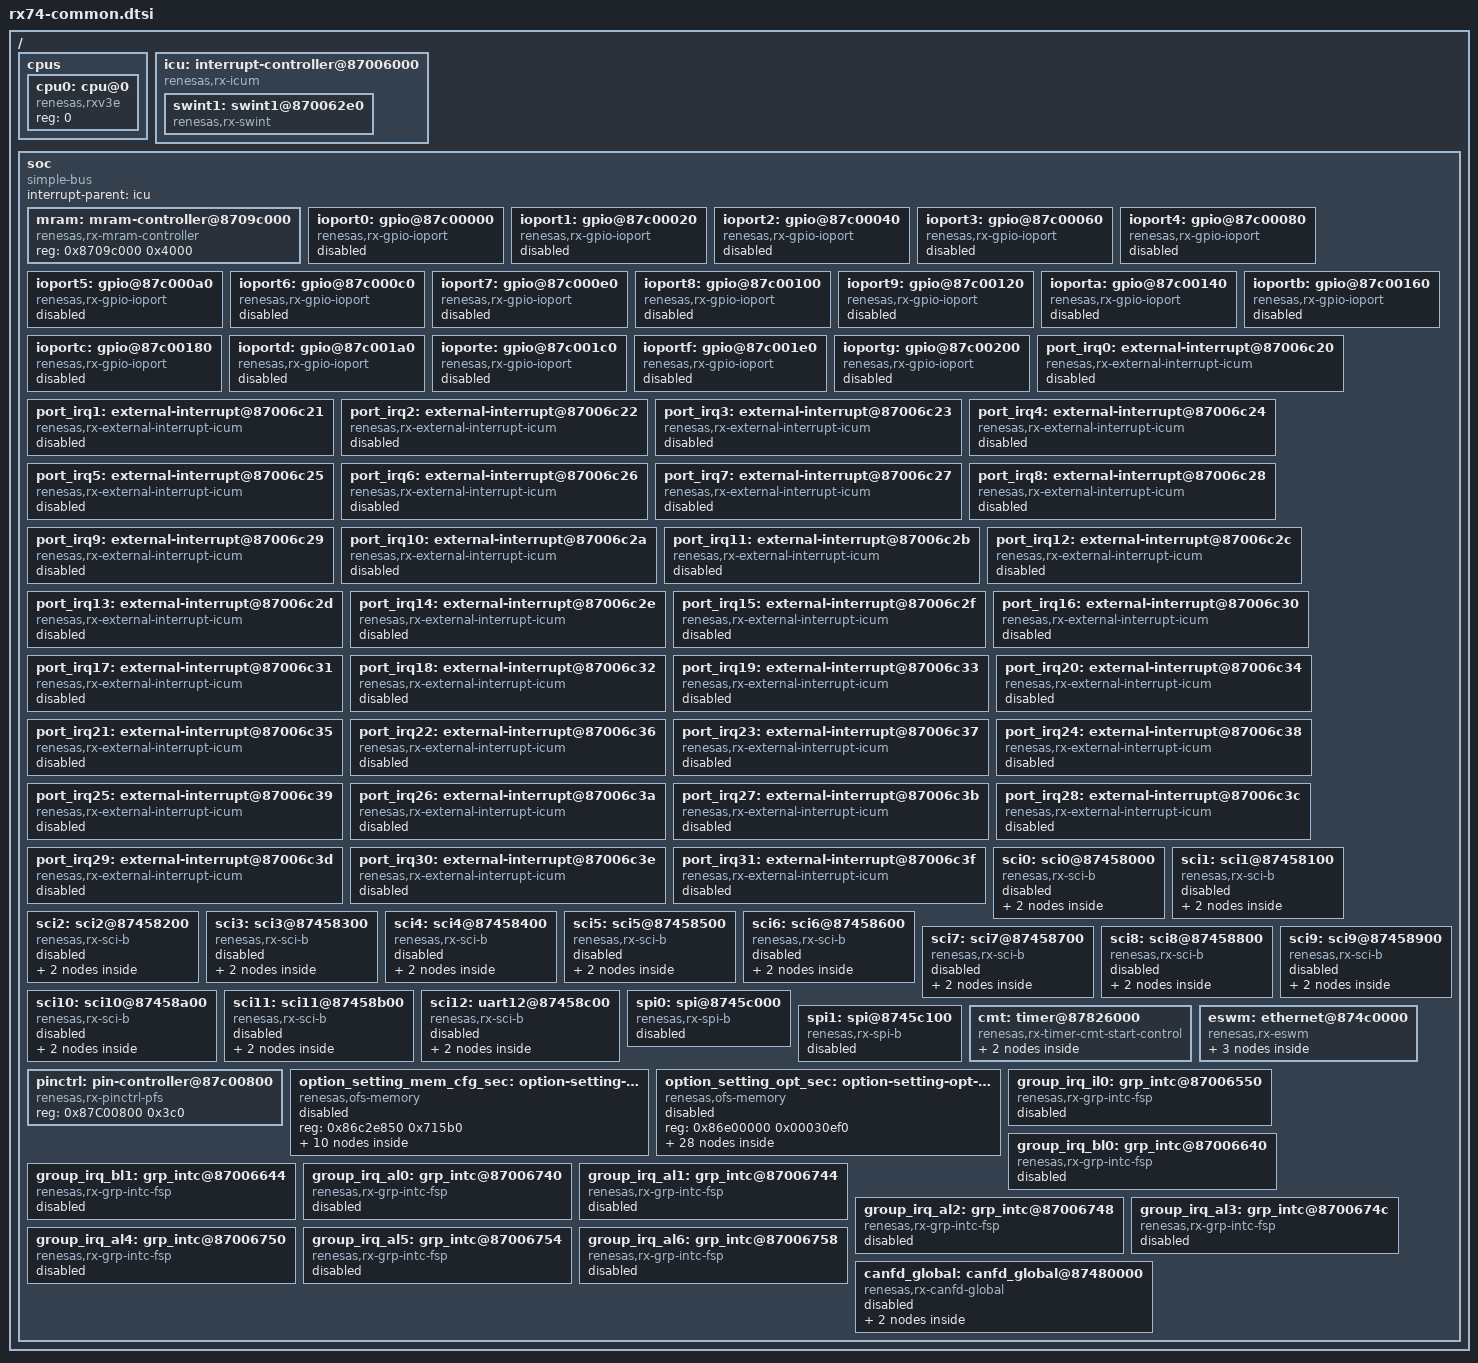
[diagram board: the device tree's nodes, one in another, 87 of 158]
/*
* Copyright (c) 2025 Renesas Electronics Corporation
*
* SPDX-License-Identifier: Apache-2.0
*/

#include <mem.h>
#include <zephyr/dt-bindings/clock/rx_clock.h>
#include <zephyr/dt-bindings/pinctrl/renesas/pinctrl-rx-pfs.h>

/ {
	#address-cells = <1>;
	#size-cells = <1>;

	cpus {
		#address-cells = <1>;
		#size-cells = <0>;

		cpu0: cpu@0 {
			compatible = "renesas,rxv3e";
			device_type = "cpu";
			reg = <0>;
			status = "okay";
		};
	};

	icu: interrupt-controller@87006000 {
		#interrupt-cells = <2>;
		#address-cells = <1>;
		#size-cells = <1>;
		compatible = "renesas,rx-icum";
		interrupt-controller;
		reg = <0x87006000 0x100>,
		<0x87006200 0x20>,
		<0x87006300 0x100>,
		<0x870062f0 0x02>,
		<0x87006c20 0x20>,
		<0x87006900 0x20>;
		reg-names = "IR", "IER", "IPR", "FIR", "IRQCR", "SLIXR";

		swint1: swint1@870062e0 {
			compatible = "renesas,rx-swint";
			reg = <0x870062e0 0x01>;
			interrupts = <27 14>;
			interrupt-parent = <&icu>;
			status = "okay";
		};
	};

	soc {
		#address-cells = <1>;
		#size-cells = <1>;
		device_type = "soc";
		compatible = "simple-bus";
		interrupt-parent = <&icu>;

		mram: mram-controller@8709c000 {
			compatible = "renesas,rx-mram-controller";
			reg = <0x8709c000 0x4000>;
			#address-cells = <1>;
			#size-cells = <1>;
			status = "okay";
		};

		ioport0: gpio@87c00000 {
			compatible = "renesas,rx-gpio-ioport";
			reg = <0x87C00000 0x20>;
			port = <0>;
			gpio-controller;
			#gpio-cells = <2>;
			ngpios = <16>;
			port-irqs = <&port_irq16 &port_irq17 &port_irq18 &port_irq19
			&port_irq20 &port_irq21 &port_irq22 &port_irq23
			&port_irq24 &port_irq25 &port_irq26 &port_irq27
			&port_irq28 &port_irq29 &port_irq30 &port_irq31>;
			port-irq-names = "port-irq16",
							 "port-irq17",
			                 "port-irq18",
			                 "port-irq19",
			                 "port-irq20",
			                 "port-irq21",
			                 "port-irq22",
			                 "port-irq23",
							 "port-irq24",
							 "port-irq25",
			                 "port-irq26",
			                 "port-irq27",
			                 "port-irq28",
			                 "port-irq29",
			                 "port-irq30",
			                 "port-irq31";
			port-irq16-pins = <0>;
			port-irq17-pins = <1>;
			port-irq18-pins = <2>;
			port-irq19-pins = <3>;
			port-irq20-pins = <4>;
			port-irq21-pins = <5>;
			port-irq22-pins = <6>;
			port-irq23-pins = <7>;
			port-irq24-pins = <8>;
			port-irq25-pins = <9>;
			port-irq26-pins = <10>;
			port-irq27-pins = <11>;
			port-irq28-pins = <12>;
			port-irq29-pins = <13>;
			port-irq30-pins = <14>;
			port-irq31-pins = <15>;
			status = "disabled";
		};

		ioport1: gpio@87c00020 {
			compatible = "renesas,rx-gpio-ioport";
			reg = <0x87C00020 0x20>;
			port = <1>;
			gpio-controller;
			#gpio-cells = <2>;
			ngpios = <16>;
			port-irqs = <&port_irq0 &port_irq1 &port_irq2 &port_irq3
			&port_irq4 &port_irq29 &port_irq30 &port_irq31
			&port_irq16 &port_irq17 &port_irq18 &port_irq19
			&port_irq20 &port_irq21 &port_irq22 &port_irq23>;
			port-irq-names = "port-irq0",
							 "port-irq1",
			                 "port-irq2",
			                 "port-irq3",
			                 "port-irq4",
			                 "port-irq29",
			                 "port-irq30",
			                 "port-irq31",
							 "port-irq16",
							 "port-irq17",
			                 "port-irq18",
			                 "port-irq19",
			                 "port-irq20",
			                 "port-irq21",
			                 "port-irq22",
			                 "port-irq23";
			port-irq0-pins = <0>;
			port-irq1-pins = <1>;
			port-irq2-pins = <2>;
			port-irq3-pins = <3>;
			port-irq4-pins = <4>;
			port-irq29-pins = <5>;
			port-irq30-pins = <6>;
			port-irq31-pins = <7>;
			port-irq16-pins = <8>;
			port-irq17-pins = <9>;
			port-irq18-pins = <10>;
			port-irq19-pins = <11>;
			port-irq20-pins = <12>;
			port-irq21-pins = <13>;
			port-irq22-pins = <14>;
			port-irq23-pins = <15>;
			status = "disabled";
		};

		ioport2: gpio@87c00040 {
			compatible = "renesas,rx-gpio-ioport";
			reg = <0x87C00040 0x20>;
			port = <2>;
			gpio-controller;
			#gpio-cells = <2>;
			ngpios = <16>;
			port-irqs = <&port_irq8 &port_irq9 &port_irq15 &port_irq3
			&port_irq12 &port_irq5 &port_irq2 &port_irq24
			&port_irq25 &port_irq26 &port_irq27 &port_irq28
			&port_irq29 &port_irq30 &port_irq31>;
			port-irq-names = "port-irq8",
					 		 "port-irq9",
							 "port-irq15",
					 		 "port-irq3",
							 "port-irq12",
					 		 "port-irq5",
							 "port-irq2",
							 "port-irq24",
							 "port-irq25",
			                 "port-irq26",
			                 "port-irq27",
			                 "port-irq28",
			                 "port-irq29",
			                 "port-irq30",
			                 "port-irq31";
			port-irq8-pins = <0>;
			port-irq9-pins = <1>;
			port-irq15-pins = <2>;
			port-irq3-pins = <3 7>;
			port-irq12-pins = <4>;
			port-irq5-pins = <5>;
			port-irq2-pins = <6>;
			port-irq24-pins = <8>;
			port-irq25-pins = <9>;
			port-irq26-pins = <10>;
			port-irq27-pins = <11>;
			port-irq28-pins = <12>;
			port-irq29-pins = <13>;
			port-irq30-pins = <14>;
			port-irq31-pins = <15>;
			status = "disabled";
		};

		ioport3: gpio@87c00060 {
			compatible = "renesas,rx-gpio-ioport";
			reg = <0x87C00060 0x20>;
			port = <3>;
			gpio-controller;
			#gpio-cells = <2>;
			ngpios = <16>;
			port-irqs = <&port_irq6 &port_irq7 &port_irq4 &port_irq1
			&port_irq0 &port_irq18 &port_irq19 &port_irq20>;
			port-irq-names = "port-irq6",
			                 "port-irq7",
			                 "port-irq4",
			                 "port-irq1",
			                 "port-irq0",
			                 "port-irq18",
			                 "port-irq19",
			                 "port-irq20";
			port-irq6-pins = <0>;
			port-irq7-pins = <1>;
			port-irq4-pins = <2>;
			port-irq1-pins = <3>;
			port-irq0-pins = <4 5>;
			port-irq18-pins = <10>;
			port-irq19-pins = <11>;
			port-irq20-pins = <12>;
			status = "disabled";
		};

		ioport4: gpio@87c00080 {
			compatible = "renesas,rx-gpio-ioport";
			reg = <0x87C00080 0x20>;
			port = <4>;
			gpio-controller;
			#gpio-cells = <2>;
			ngpios = <16>;
			port-irqs = <&port_irq8 &port_irq9 &port_irq10 &port_irq11
			&port_irq12 &port_irq13 &port_irq14 &port_irq15
			&port_irq24 &port_irq25 &port_irq26 &port_irq27
			&port_irq28 &port_irq29 &port_irq30 &port_irq31>;
			port-irq-names = "port-irq8",
							 "port-irq9",
			                 "port-irq10",
			                 "port-irq11",
			                 "port-irq12",
			                 "port-irq13",
			                 "port-irq14",
			                 "port-irq15",
							 "port-irq24",
							 "port-irq25",
			                 "port-irq26",
			                 "port-irq27",
			                 "port-irq28",
			                 "port-irq29",
			                 "port-irq30",
			                 "port-irq31";
			port-irq8-pins = <0>;
			port-irq9-pins = <1>;
			port-irq10-pins = <2>;
			port-irq11-pins = <3>;
			port-irq12-pins = <4>;
			port-irq13-pins = <5>;
			port-irq14-pins = <6>;
			port-irq15-pins = <7>;
			port-irq24-pins = <8>;
			port-irq25-pins = <9>;
			port-irq26-pins = <10>;
			port-irq27-pins = <11>;
			port-irq28-pins = <12>;
			port-irq29-pins = <13>;
			port-irq30-pins = <14>;
			port-irq31-pins = <15>;
			status = "disabled";
		};

		ioport5: gpio@87c000a0 {
			compatible = "renesas,rx-gpio-ioport";
			reg = <0x87C000A0 0x20>;
			port = <5>;
			gpio-controller;
			#gpio-cells = <2>;
			ngpios = <16>;
			port-irqs = <&port_irq0 &port_irq1 &port_irq2 &port_irq3
			&port_irq4 &port_irq10 &port_irq6 &port_irq7
			&port_irq16 &port_irq17 &port_irq18 &port_irq19
			&port_irq20 &port_irq21 &port_irq22 &port_irq23>;
			port-irq-names = "port-irq0",
							 "port-irq1",
			                 "port-irq2",
			                 "port-irq3",
			                 "port-irq4",
			                 "port-irq10",
			                 "port-irq6",
			                 "port-irq7",
							 "port-irq16",
							 "port-irq17",
			                 "port-irq18",
			                 "port-irq19",
			                 "port-irq20",
			                 "port-irq21",
			                 "port-irq22",
			                 "port-irq23";
			port-irq0-pins = <0>;
			port-irq1-pins = <1>;
			port-irq2-pins = <2>;
			port-irq3-pins = <3>;
			port-irq4-pins = <4>;
			port-irq10-pins = <5>;
			port-irq6-pins = <6>;
			port-irq7-pins = <7>;
			port-irq16-pins = <8>;
			port-irq17-pins = <9>;
			port-irq18-pins = <10>;
			port-irq19-pins = <11>;
			port-irq20-pins = <12>;
			port-irq21-pins = <13>;
			port-irq22-pins = <14>;
			port-irq23-pins = <15>;
			status = "disabled";
		};

		ioport6: gpio@87c000c0 {
			compatible = "renesas,rx-gpio-ioport";
			reg = <0x87C000C0 0x20>;
			port = <6>;
			gpio-controller;
			#gpio-cells = <2>;
			ngpios = <8>;
			port-irqs = <&port_irq0 &port_irq1 &port_irq2 &port_irq3
			&port_irq4 &port_irq13 &port_irq14 &port_irq15>;
			port-irq-names = "port-irq0",
							 "port-irq1",
			                 "port-irq2",
			                 "port-irq3",
			                 "port-irq4",
			                 "port-irq13",
			                 "port-irq14",
			                 "port-irq15";
			port-irq0-pins = <0>;
			port-irq1-pins = <1>;
			port-irq2-pins = <2>;
			port-irq3-pins = <3>;
			port-irq4-pins = <4>;
			port-irq13-pins = <5>;
			port-irq14-pins = <6>;
			port-irq15-pins = <7>;
			status = "disabled";
		};

		ioport7: gpio@87c000e0 {
			compatible = "renesas,rx-gpio-ioport";
			reg = <0x87C000E0 0x20>;
			port = <7>;
			gpio-controller;
			#gpio-cells = <2>;
			ngpios = <16>;
			port-irqs = <&port_irq0 &port_irq1 &port_irq10 &port_irq8
			&port_irq12 &port_irq13 &port_irq14 &port_irq7
			&port_irq16 &port_irq17 &port_irq18 &port_irq19
			&port_irq20 &port_irq21 &port_irq22 &port_irq23>;
			port-irq-names = "port-irq0",
							 "port-irq1",
			                 "port-irq10",
			                 "port-irq8",
			                 "port-irq12",
			                 "port-irq13",
			                 "port-irq14",
			                 "port-irq7",
							 "port-irq16",
							 "port-irq17",
			                 "port-irq18",
			                 "port-irq19",
			                 "port-irq20",
			                 "port-irq21",
			                 "port-irq22",
			                 "port-irq23";
			port-irq0-pins = <0>;
			port-irq1-pins = <1>;
			port-irq10-pins = <2>;
			port-irq8-pins = <3>;
			port-irq12-pins = <4>;
			port-irq13-pins = <5>;
			port-irq14-pins = <6>;
			port-irq7-pins = <7>;
			port-irq16-pins = <8>;
			port-irq17-pins = <9>;
			port-irq18-pins = <10>;
			port-irq19-pins = <11>;
			port-irq20-pins = <12>;
			port-irq21-pins = <13>;
			port-irq22-pins = <14>;
			port-irq23-pins = <15>;
			status = "disabled";
		};

		ioport8: gpio@87c00100 {
			compatible = "renesas,rx-gpio-ioport";
			reg = <0x87C00100 0x20>;
			port = <8>;
			gpio-controller;
			#gpio-cells = <2>;
			ngpios = <16>;
			port-irqs = <&port_irq8 &port_irq9 &port_irq2 &port_irq3
			&port_irq4 &port_irq5 &port_irq14 &port_irq15>;
			port-irq-names = "port-irq8",
							 "port-irq9",
			                 "port-irq2",
			                 "port-irq3",
			                 "port-irq4",
			                 "port-irq5",
			                 "port-irq14",
			                 "port-irq15";
			port-irq8-pins = <0>;
			port-irq9-pins = <1>;
			port-irq2-pins = <2>;
			port-irq3-pins = <3>;
			port-irq4-pins = <4>;
			port-irq5-pins = <5>;
			port-irq14-pins = <6>;
			port-irq15-pins = <7>;
			status = "disabled";
		};

		ioport9: gpio@87c00120 {
			compatible = "renesas,rx-gpio-ioport";
			reg = <0x87C00120 0x20>;
			port = <9>;
			gpio-controller;
			#gpio-cells = <2>;
			ngpios = <16>;
			port-irqs = <&port_irq0 &port_irq9 &port_irq10 &port_irq11
			&port_irq12 &port_irq13 &port_irq14 &port_irq15>;
			port-irq-names = "port-irq0",
							 "port-irq9",
			                 "port-irq10",
			                 "port-irq11",
			                 "port-irq12",
			                 "port-irq13",
			                 "port-irq14",
			                 "port-irq15";
			port-irq0-pins = <0>;
			port-irq9-pins = <1>;
			port-irq10-pins = <2>;
			port-irq11-pins = <3>;
			port-irq12-pins = <4>;
			port-irq13-pins = <5>;
			port-irq14-pins = <6>;
			port-irq15-pins = <7>;
			status = "disabled";
		};

		ioporta: gpio@87c00140 {
			compatible = "renesas,rx-gpio-ioport";
			reg = <0x87C00140 0x20>;
			port = <10>;
			gpio-controller;
			#gpio-cells = <2>;
			ngpios = <8>;
			port-irqs = <&port_irq1 &port_irq5 &port_irq6 &port_irq7
			&port_irq10 &port_irq11 &port_irq14>;
			port-irq-names = "port-irq1",
			                 "port-irq5",
			                 "port-irq6",
			                 "port-irq7",
			                 "port-irq10",
			                 "port-irq11",
			                 "port-irq14";
			port-irq1-pins = <0>;
			port-irq5-pins = <4 5>;
			port-irq6-pins = <3>;
			port-irq7-pins = <7>;
			port-irq10-pins = <2>;
			port-irq11-pins = <1>;
			port-irq14-pins = <6>;
			status = "disabled";
		};

		ioportb: gpio@87c00160 {
			compatible = "renesas,rx-gpio-ioport";
			reg = <0x87C00160 0x20>;
			port = <11>;
			gpio-controller;
			#gpio-cells = <2>;
			ngpios = <8>;
			port-irqs = <&port_irq12 &port_irq4 &port_irq2 &port_irq3
			&port_irq13 &port_irq6 &port_irq15>;
			port-irq-names = "port-irq12",
			                 "port-irq4",
			                 "port-irq2",
			                 "port-irq3",
			                 "port-irq13",
			                 "port-irq6",
							 "port-irq15";
			port-irq12-pins = <0>;
			port-irq4-pins = <1 4>;
			port-irq2-pins = <2>;
			port-irq3-pins = <3>;
			port-irq13-pins = <5>;
			port-irq6-pins = <6>;
			port-irq15-pins = <15>;
			status = "disabled";
		};

		ioportc: gpio@87c00180 {
			compatible = "renesas,rx-gpio-ioport";
			reg = <0x87C00180 0x20>;
			port = <12>;
			gpio-controller;
			#gpio-cells = <2>;
			ngpios = <8>;
			port-irqs = <&port_irq14 &port_irq10 &port_irq11 &port_irq12
			&port_irq5 &port_irq13 &port_irq14>;
			port-irq-names = "port-irq14",
			                 "port-irq10",
			                 "port-irq11",
			                 "port-irq12",
			                 "port-irq5",
			                 "port-irq13",
			                 "port-irq14";
			port-irq14-pins = <0>;
			port-irq10-pins = <2>;
			port-irq12-pins = <1 4>;
			port-irq11-pins = <3>;
			port-irq5-pins = <5>;
			port-irq13-pins = <6>;
			port-irq14-pins = <7>;
			status = "disabled";
		};

		ioportd: gpio@87c001a0 {
			compatible = "renesas,rx-gpio-ioport";
			reg = <0x87C001A0 0x20>;
			port = <13>;
			gpio-controller;
			#gpio-cells = <2>;
			ngpios = <8>;
			port-irqs = <&port_irq0 &port_irq1 &port_irq2 &port_irq3
			&port_irq4 &port_irq5 &port_irq6 &port_irq7>;
			port-irq-names = "port-irq0",
			                 "port-irq1",
			                 "port-irq2",
			                 "port-irq3",
			                 "port-irq4",
			                 "port-irq5",
			                 "port-irq6",
			                 "port-irq7";
			port-irq0-pins = <0>;
			port-irq1-pins = <1>;
			port-irq2-pins = <2>;
			port-irq3-pins = <3>;
			port-irq4-pins = <4>;
			port-irq5-pins = <5>;
			port-irq6-pins = <6>;
			port-irq7-pins = <7>;
			status = "disabled";
		};

		ioporte: gpio@87c001c0 {
			compatible = "renesas,rx-gpio-ioport";
			reg = <0x87C001C0 0x20>;
			port = <14>;
			gpio-controller;
			#gpio-cells = <2>;
			ngpios = <8>;
			port-irqs = <&port_irq8 &port_irq9 &port_irq7 &port_irq11
			&port_irq12 &port_irq5 &port_irq6>;
			port-irq-names = "port-irq8",
			                 "port-irq9",
			                 "port-irq7",
			                 "port-irq11",
			                 "port-irq12",
			                 "port-irq5",
			                 "port-irq6";
			port-irq8-pins = <0>;
			port-irq9-pins = <1>;
			port-irq7-pins = <2 7>;
			port-irq11-pins = <3>;
			port-irq12-pins = <4>;
			port-irq5-pins = <5>;
			port-irq6-pins = <6>;
			status = "disabled";
		};

		ioportf: gpio@87c001e0 {
			compatible = "renesas,rx-gpio-ioport";
			reg = <0x87C001E0 0x20>;
			port = <15>;
			gpio-controller;
			#gpio-cells = <2>;
			ngpios = <10>;
			port-irqs = <&port_irq16 &port_irq17>;
			port-irq-names = "port-irq16", "port-irq17";
			port-irq16-pins = <8>;
			port-irq17-pins = <9>;
			status = "disabled";
		};

		ioportg: gpio@87c00200 {
			compatible = "renesas,rx-gpio-ioport";
			reg = <0x87C00200 0x20>;
			port = <16>;
			gpio-controller;
			#gpio-cells = <2>;
			ngpios = <16>;
			port-irqs = <&port_irq8 &port_irq9 &port_irq10 &port_irq11
			&port_irq12 &port_irq13 &port_irq14 &port_irq15>;
			port-irq-names = "port-irq8",
							 "port-irq9",
			                 "port-irq10",
			                 "port-irq11",
			                 "port-irq12",
			                 "port-irq13",
			                 "port-irq14",
			                 "port-irq15";
			port-irq8-pins = <0>;
			port-irq9-pins = <1>;
			port-irq10-pins = <2>;
			port-irq11-pins = <3>;
			port-irq12-pins = <4>;
			port-irq13-pins = <5>;
			port-irq14-pins = <6>;
			port-irq15-pins = <7>;
			status = "disabled";
		};

		port_irq0: external-interrupt@87006c20 {
			compatible = "renesas,rx-external-interrupt-icum";
			reg = <0x87006C20 0x1>;
			interrupts = <64 12>;
			channel = <0>;
			renesas,sample-clock-div = <64>;
			#port-irq-cells = <0>;
			status = "disabled";
		};

		port_irq1: external-interrupt@87006c21 {
			compatible = "renesas,rx-external-interrupt-icum";
			reg = <0x87006C21 0x1>;
			interrupts = <65 12>;
			channel = <1>;
			renesas,sample-clock-div = <64>;
			#port-irq-cells = <0>;
			status = "disabled";
		};

		port_irq2: external-interrupt@87006c22 {
			compatible = "renesas,rx-external-interrupt-icum";
			reg = <0x87006C22 0x1>;
			interrupts = <66 12>;
			channel = <2>;
			renesas,sample-clock-div = <64>;
			#port-irq-cells = <0>;
			status = "disabled";
		};

		port_irq3: external-interrupt@87006c23 {
			compatible = "renesas,rx-external-interrupt-icum";
			reg = <0x87006C23 0x1>;
			interrupts = <67 12>;
			channel = <3>;
			renesas,sample-clock-div = <64>;
			#port-irq-cells = <0>;
			status = "disabled";
		};

		port_irq4: external-interrupt@87006c24 {
			compatible = "renesas,rx-external-interrupt-icum";
			reg = <0x87006C24 0x1>;
			interrupts = <68 12>;
			channel = <4>;
			renesas,sample-clock-div = <64>;
			#port-irq-cells = <0>;
			status = "disabled";
		};

		port_irq5: external-interrupt@87006c25 {
			compatible = "renesas,rx-external-interrupt-icum";
			reg = <0x87006C25 0x1>;
			interrupts = <69 12>;
			channel = <5>;
			renesas,sample-clock-div = <64>;
			#port-irq-cells = <0>;
			status = "disabled";
		};

		port_irq6: external-interrupt@87006c26 {
			compatible = "renesas,rx-external-interrupt-icum";
			reg = <0x87006C26 0x1>;
			interrupts = <70 12>;
			channel = <6>;
			renesas,sample-clock-div = <64>;
			#port-irq-cells = <0>;
			status = "disabled";
		};

		port_irq7: external-interrupt@87006c27 {
			compatible = "renesas,rx-external-interrupt-icum";
			reg = <0x87006C27 0x1>;
			interrupts = <71 12>;
			channel = <7>;
			renesas,sample-clock-div = <64>;
			#port-irq-cells = <0>;
			status = "disabled";
		};

		port_irq8: external-interrupt@87006c28 {
			compatible = "renesas,rx-external-interrupt-icum";
			reg = <0x87006C28 0x1>;
			interrupts = <72 12>;
			channel = <8>;
			renesas,sample-clock-div = <64>;
			#port-irq-cells = <0>;
			status = "disabled";
		};

		port_irq9: external-interrupt@87006c29 {
			compatible = "renesas,rx-external-interrupt-icum";
			reg = <0x87006C29 0x1>;
			interrupts = <73 12>;
			channel = <9>;
			renesas,sample-clock-div = <64>;
			#port-irq-cells = <0>;
			status = "disabled";
		};

		port_irq10: external-interrupt@87006c2a {
			compatible = "renesas,rx-external-interrupt-icum";
			reg = <0x87006C2a 0x1>;
			interrupts = <74 12>;
			channel = <10>;
			renesas,sample-clock-div = <64>;
			#port-irq-cells = <0>;
			status = "disabled";
		};

		port_irq11: external-interrupt@87006c2b {
			compatible = "renesas,rx-external-interrupt-icum";
			reg = <0x87006C2B 0x1>;
			interrupts = <75 12>;
			channel = <11>;
			renesas,sample-clock-div = <64>;
			#port-irq-cells = <0>;
			status = "disabled";
		};

		port_irq12: external-interrupt@87006c2c {
			compatible = "renesas,rx-external-interrupt-icum";
			reg = <0x87006C2C 0x1>;
			interrupts = <76 12>;
			channel = <12>;
			renesas,sample-clock-div = <64>;
			#port-irq-cells = <0>;
			status = "disabled";
		};

		port_irq13: external-interrupt@87006c2d {
			compatible = "renesas,rx-external-interrupt-icum";
			reg = <0x87006C2D 0x1>;
			interrupts = <77 12>;
			channel = <13>;
			renesas,sample-clock-div = <64>;
			#port-irq-cells = <0>;
			status = "disabled";
		};

		port_irq14: external-interrupt@87006c2e {
			compatible = "renesas,rx-external-interrupt-icum";
			reg = <0x87006C2E 0x1>;
			interrupts = <78 12>;
			channel = <14>;
			renesas,sample-clock-div = <64>;
			#port-irq-cells = <0>;
			status = "disabled";
		};

		port_irq15: external-interrupt@87006c2f {
			compatible = "renesas,rx-external-interrupt-icum";
			reg = <0x87006C2F 0x1>;
			interrupts = <79 12>;
			channel = <15>;
			renesas,sample-clock-div = <64>;
			#port-irq-cells = <0>;
			status = "disabled";
		};

		port_irq16: external-interrupt@87006c30 {
			compatible = "renesas,rx-external-interrupt-icum";
			reg = <0x87006C30 0x1>;
			interrupts = <128 12>;
			channel = <16>;
			renesas,sample-clock-div = <64>;
			#port-irq-cells = <0>;
			status = "disabled";
		};

		port_irq17: external-interrupt@87006c31 {
			compatible = "renesas,rx-external-interrupt-icum";
			reg = <0x87006C31 0x1>;
			interrupts = <129 12>;
			channel = <17>;
			renesas,sample-clock-div = <64>;
			#port-irq-cells = <0>;
			status = "disabled";
		};

		port_irq18: external-interrupt@87006c32 {
			compatible = "renesas,rx-external-interrupt-icum";
			reg = <0x87006C32 0x1>;
			interrupts = <130 12>;
			channel = <18>;
			renesas,sample-clock-div = <64>;
			#port-irq-cells = <0>;
			status = "disabled";
		};

		port_irq19: external-interrupt@87006c33 {
			compatible = "renesas,rx-external-interrupt-icum";
			reg = <0x87006C33 0x1>;
			interrupts = <131 12>;
			channel = <19>;
			renesas,sample-clock-div = <64>;
			#port-irq-cells = <0>;
			status = "disabled";
		};

		port_irq20: external-interrupt@87006c34 {
			compatible = "renesas,rx-external-interrupt-icum";
			reg = <0x87006C34 0x1>;
			interrupts = <132 12>;
			channel = <20>;
			renesas,sample-clock-div = <64>;
			#port-irq-cells = <0>;
			status = "disabled";
		};

		port_irq21: external-interrupt@87006c35 {
			compatible = "renesas,rx-external-interrupt-icum";
			reg = <0x87006C35 0x1>;
			interrupts = <133 12>;
			channel = <21>;
			renesas,sample-clock-div = <64>;
			#port-irq-cells = <0>;
			status = "disabled";
		};

		port_irq22: external-interrupt@87006c36 {
			compatible = "renesas,rx-external-interrupt-icum";
			reg = <0x87006C36 0x1>;
			interrupts = <134 12>;
			channel = <22>;
			renesas,sample-clock-div = <64>;
			#port-irq-cells = <0>;
			status = "disabled";
		};

		port_irq23: external-interrupt@87006c37 {
			compatible = "renesas,rx-external-interrupt-icum";
			reg = <0x87006C37 0x1>;
			interrupts = <135 12>;
			channel = <23>;
			renesas,sample-clock-div = <64>;
			#port-irq-cells = <0>;
			status = "disabled";
		};

		port_irq24: external-interrupt@87006c38 {
			compatible = "renesas,rx-external-interrupt-icum";
			reg = <0x87006C38 0x1>;
			interrupts = <136 12>;
			channel = <24>;
			renesas,sample-clock-div = <64>;
			#port-irq-cells = <0>;
			status = "disabled";
		};

		port_irq25: external-interrupt@87006c39 {
			compatible = "renesas,rx-external-interrupt-icum";
			reg = <0x87006C39 0x1>;
			interrupts = <137 12>;
			channel = <25>;
			renesas,sample-clock-div = <64>;
			#port-irq-cells = <0>;
			status = "disabled";
		};

		port_irq26: external-interrupt@87006c3a {
			compatible = "renesas,rx-external-interrupt-icum";
			reg = <0x87006C3A 0x1>;
			interrupts = <138 12>;
			channel = <26>;
			renesas,sample-clock-div = <64>;
			#port-irq-cells = <0>;
			status = "disabled";
		};

		port_irq27: external-interrupt@87006c3b {
			compatible = "renesas,rx-external-interrupt-icum";
			reg = <0x87006C3B 0x1>;
			interrupts = <139 12>;
			channel = <27>;
			renesas,sample-clock-div = <64>;
			#port-irq-cells = <0>;
			status = "disabled";
		};

		port_irq28: external-interrupt@87006c3c {
			compatible = "renesas,rx-external-interrupt-icum";
			reg = <0x87006C3C 0x1>;
			interrupts = <140 12>;
			channel = <28>;
			renesas,sample-clock-div = <64>;
			#port-irq-cells = <0>;
			status = "disabled";
		};

		port_irq29: external-interrupt@87006c3d {
			compatible = "renesas,rx-external-interrupt-icum";
			reg = <0x87006C3D 0x1>;
			interrupts = <141 12>;
			channel = <29>;
			renesas,sample-clock-div = <64>;
			#port-irq-cells = <0>;
			status = "disabled";
		};

		port_irq30: external-interrupt@87006c3e {
			compatible = "renesas,rx-external-interrupt-icum";
			reg = <0x87006C3E 0x1>;
			interrupts = <142 12>;
			channel = <30>;
			renesas,sample-clock-div = <64>;
			#port-irq-cells = <0>;
			status = "disabled";
		};

		port_irq31: external-interrupt@87006c3f {
			compatible = "renesas,rx-external-interrupt-icum";
			reg = <0x87006C3F 0x1>;
			interrupts = <143 12>;
			channel = <31>;
			renesas,sample-clock-div = <64>;
			#port-irq-cells = <0>;
			status = "disabled";
		};

		sci0: sci0@87458000 {
			compatible = "renesas,rx-sci-b";
			reg = <0x87458000 0x100>;
			clocks = <&sciclk MSTPB 31>;
			status = "disabled";
			channel = <0>;

			uart {
				compatible = "renesas,rx-uart-sci-b";
				status = "disabled";
			};

			i2c {
				compatible = "renesas,rx-i2c-sci-b";
				#address-cells = <1>;
				#size-cells = <0>;
				status = "disabled";
			};
		};

		sci1: sci1@87458100 {
			compatible = "renesas,rx-sci-b";
			reg = <0x87458100 0x100>;
			clocks = <&sciclk MSTPB 30>;
			interrupts-extended = <&icu 145 1>,
					      <&group_irq_al0 3 1>;
			interrupt-names = "txi", "tei";
			status = "disabled";
			channel = <1>;

			uart {
				compatible = "renesas,rx-uart-sci-b";
				status = "disabled";
			};

			i2c {
				compatible = "renesas,rx-i2c-sci-b";
				#address-cells = <1>;
				#size-cells = <0>;
				status = "disabled";
			};
		};

		sci2: sci2@87458200 {
			compatible = "renesas,rx-sci-b";
			reg = <0x87458200 0x100>;
			clocks = <&sciclk MSTPB 29>;
			status = "disabled";
			channel = <2>;

			uart {
				compatible = "renesas,rx-uart-sci-b";
				status = "disabled";
			};

			i2c {
				compatible = "renesas,rx-i2c-sci-b";
				#address-cells = <1>;
				#size-cells = <0>;
				status = "disabled";
			};
		};

		sci3: sci3@87458300 {
			compatible = "renesas,rx-sci-b";
			reg = <0x87458300 0x100>;
			clocks = <&sciclk MSTPB 28>;
			status = "disabled";
			channel = <3>;

			uart {
				compatible = "renesas,rx-uart-sci-b";
				status = "disabled";
			};

			i2c {
				compatible = "renesas,rx-i2c-sci-b";
				#address-cells = <1>;
				#size-cells = <0>;
				status = "disabled";
			};
		};

		sci4: sci4@87458400 {
			compatible = "renesas,rx-sci-b";
			reg = <0x87458400 0x100>;
			clocks = <&sciclk MSTPB 27>;
			status = "disabled";
			channel = <4>;

			uart {
				compatible = "renesas,rx-uart-sci-b";
				status = "disabled";
			};

			i2c {
				compatible = "renesas,rx-i2c-sci-b";
				#address-cells = <1>;
				#size-cells = <0>;
				status = "disabled";
			};
		};

		sci5: sci5@87458500 {
			compatible = "renesas,rx-sci-b";
			reg = <0x87458500 0x100>;
			clocks = <&sciclk MSTPB 26>;
			status = "disabled";
			channel = <5>;

			uart {
				compatible = "renesas,rx-uart-sci-b";
				status = "disabled";
			};

			i2c {
				compatible = "renesas,rx-i2c-sci-b";
				#address-cells = <1>;
				#size-cells = <0>;
				status = "disabled";
			};
		};

		sci6: sci6@87458600 {
			compatible = "renesas,rx-sci-b";
			reg = <0x87458600 0x100>;
			clocks = <&sciclk MSTPB 25>;
			status = "disabled";
			channel = <6>;

			uart {
				compatible = "renesas,rx-uart-sci-b";
				status = "disabled";
			};

			i2c {
				compatible = "renesas,rx-i2c-sci-b";
				#address-cells = <1>;
				#size-cells = <0>;
				status = "disabled";
			};
		};

		sci7: sci7@87458700 {
			compatible = "renesas,rx-sci-b";
			reg = <0x87458700 0x100>;
			clocks = <&sciclk MSTPB 24>;
			status = "disabled";
			channel = <7>;

			uart {
				compatible = "renesas,rx-uart-sci-b";
				status = "disabled";
			};

			i2c {
				compatible = "renesas,rx-i2c-sci-b";
				#address-cells = <1>;
				#size-cells = <0>;
				status = "disabled";
			};
		};

		sci8: sci8@87458800 {
			compatible = "renesas,rx-sci-b";
			reg = <0x87458800 0x100>;
			clocks = <&sciclk MSTPB 23>;
			status = "disabled";
			channel = <8>;

			uart {
				compatible = "renesas,rx-uart-sci-b";
				status = "disabled";
			};

			i2c {
				compatible = "renesas,rx-i2c-sci-b";
				#address-cells = <1>;
				#size-cells = <0>;
				status = "disabled";
			};
		};

		sci9: sci9@87458900 {
			compatible = "renesas,rx-sci-b";
			reg = <0x87458900 0x100>;
			clocks = <&sciclk MSTPB 22>;
			status = "disabled";
			channel = <9>;

			uart {
				compatible = "renesas,rx-uart-sci-b";
				status = "disabled";
			};

			i2c {
				compatible = "renesas,rx-i2c-sci-b";
				#address-cells = <1>;
				#size-cells = <0>;
				status = "disabled";
			};
		};

		sci10: sci10@87458a00 {
			compatible = "renesas,rx-sci-b";
			reg = <0x87458a00 0x100>;
			clocks = <&sciclk MSTPB 21>;
			status = "disabled";
			channel = <10>;

			uart {
				compatible = "renesas,rx-uart-sci-b";
				status = "disabled";
			};

			i2c {
				compatible = "renesas,rx-i2c-sci-b";
				#address-cells = <1>;
				#size-cells = <0>;
				status = "disabled";
			};
		};

		sci11: sci11@87458b00 {
			compatible = "renesas,rx-sci-b";
			reg = <0x87458b00 0x100>;
			clocks = <&sciclk MSTPB 20>;
			status = "disabled";
			channel = <11>;

			uart {
				compatible = "renesas,rx-uart-sci-b";
				status = "disabled";
			};

			i2c {
				compatible = "renesas,rx-i2c-sci-b";
				#address-cells = <1>;
				#size-cells = <0>;
				status = "disabled";
			};
		};

		sci12: uart12@87458c00 {
			compatible = "renesas,rx-sci-b";
			interrupts-extended = <&icu 144 1>, <&icu 145 1>,
					      <&group_irq_al1 6 1>, <&group_irq_al1 7 1>;
			interrupt-names = "rxi", "txi", "tei", "eri";
			reg = <0x87458c00 0x100>;
			clocks = <&sciclk MSTPB 0>;
			status = "disabled";
			channel = <12>;

			uart {
				compatible = "renesas,rx-uart-sci-b";
				status = "disabled";
			};

			i2c {
				compatible = "renesas,rx-i2c-sci-b";
				#address-cells = <1>;
				#size-cells = <0>;
				status = "disabled";
			};
		};

		spi0: spi@8745c000 {
			compatible = "renesas,rx-spi-b";
			#address-cells = <1>;
			#size-cells = <0>;
			channel = <0>;
			clocks = <&pclka MSTPB 19>;
			clock-names = "spiclk";
			interrupts-extended = <&icu 172 1>, <&icu 173 1>, <&icu 174 1>,
					      <&group_irq_al1 24 1>;
			interrupt-names = "spri", "spti", "spci", "spei";
			reg = <0x8745c000 0x100>;
			status = "disabled";
		};

		spi1: spi@8745c100 {
			compatible = "renesas,rx-spi-b";
			#address-cells = <1>;
			#size-cells = <0>;
			channel = <1>;
			clocks = <&pclka MSTPB 19>;
			clock-names = "spiclk";
			interrupts-extended = <&icu 175 1>, <&icu 176 1>, <&icu 177 1>,
					      <&group_irq_al1 26 1>;
			interrupt-names = "spri", "spti", "spci", "spei";
			reg = <0x8745c100 0x100>;
			status = "disabled";
		};

		cmt: timer@87826000 {
			compatible = "renesas,rx-timer-cmt-start-control";
			#address-cells = <1>;
			#size-cells = <1>;
			reg = <0x87826000 0x02>;
			clocks = <&pclkb MSTPF 15>;
			reg-names = "CMSTR0";
			status = "okay";

			cmt0: timer@87826002 {
				compatible = "renesas,rx-timer-cmt";
				#address-cells = <1>;
				#size-cells = <1>;
				reg = <0x87826002 0x02>,
				<0x87826004 0x02>,
				<0x87826006 0x02>;
				reg-names = "CMCR", "CMCNT", "CMCOR";
				interrupts = <28 1>;
				interrupt-names = "cmi";
				status = "okay";
			};

			cmt1: timer@87826008 {
				compatible = "renesas,rx-timer-cmt";
				reg = <0x87826008 0x02>,
				<0x8782600A 0x02>,
				<0x8782600C 0x02>;
				reg-names = "CMCR", "CMCNT", "CMCOR";
				interrupts = <29 1>;
				interrupt-names = "cmi";
				status = "disabled";
			};
		};

		pinctrl: pin-controller@87c00800 {
			compatible = "renesas,rx-pinctrl-pfs";
			reg = <0x87C00800 0x3c0>;
			status = "okay";
		};

		eswm: ethernet@874c0000 {
			compatible = "renesas,rx-eswm";
			reg = <0x874C0000 0xE000>;
			#address-cells = <1>;
			#size-cells = <1>;

			clocks = <&iclk 0 0>,
				 <&pclka MSTPC 30>,
				 <&eswclk MSTPC 30>,
				 <&eswphyclk MSTPC 28>;
			clock-names = "iclk", "pclk", "esw", "eswphy";
			ranges;

			mdio0: mdio {
				compatible = "renesas,rx-rmac-mdio";
				channel = <0>;
				#address-cells = <1>;
				#size-cells = <0>;
				clocks = <&ethphyclk MSTPC 28>;
				clock-names = "ethphy";
				status = "disabled";
			};

			rmac0: ethernet@874cb000 {
				compatible = "renesas,rx-rmac";
				channel = <0>;
				reg = <0x874CB000 0x1000>;
				interrupts-extended = <&group_irq_al4 12 1>;
				interrupt-names = "gwdi";
				local-mac-address = [00 11 22 33 44 55];
				phy-connection-type = "gmii";
				status = "disabled";


			};

			rmac1: ethernet@874cd000 {
				compatible = "renesas,rx-rmac";
				reg = <0x874CD000 0x1000>;
				channel = <1>;
				interrupts-extended = <&group_irq_al4 12 1>;
				interrupt-names = "gwdi";
				local-mac-address = [00 11 22 33 44 55];
				phy-connection-type = "gmii";
				status = "disabled";
			};
		};

		option_setting_mem_cfg_sec: option-setting-mem-cfg-sec@86c2e850 {
			compatible = "renesas,ofs-memory";
			reg = <0x86c2e850 0x715b0>;
			#address-cells = <1>;
			#size-cells = <1>;
			status = "disabled";

			option_setting_dualsel: option-setting-dualsel0@86c2e850 {
				compatible = "zephyr,memory-region";
				zephyr,memory-region = "OPTION_SETTING_DUALSEL";
				reg = <0x86c2e850 0x4>;
				status = "disabled";
			};

			option_setting_sas: option-setting-sas@86c2e870 {
				compatible = "zephyr,memory-region";
				zephyr,memory-region = "OPTION_SETTING_SAS";
				reg = <0x86c2e870 0x4>;
				status = "disabled";
			};

			option_setting_sas2: option-setting-sas2@86c2e874 {
				compatible = "zephyr,memory-region";
				reg = <0x86c2e874 0x4>;
				zephyr,memory-region = "OPTION_SETTING_SAS2";
				status = "disabled";
			};

			option_setting_banksel_sec: option-setting-banksel-sec@86c2e9b0 {
				compatible = "zephyr,memory-region";
				reg = <0x86c2e9b0 0x4>;
				zephyr,memory-region = "OPTION_SETTING_BANKSEL_SEC";
				status = "disabled";
			};

			option_setting_blsel_sec: option-setting-blsel-sec@86c2e9c0 {
				compatible = "zephyr,memory-region";
				reg = <0x86c2e9c0 0x4>;
				zephyr,memory-region = "OPTION_SETTING_BLSEL_SEC";
				status = "disabled";
			};

			option_setting_banksel_sel: option-setting-banksel-sel@86c2e9e0 {
				compatible = "zephyr,memory-region";
				reg = <0x86c2e9e0 0x4>;
				zephyr,memory-region = "OPTION_SETTING_BANKSEL_SEL";
				status = "disabled";
			};

			option_setting_blsel_sel: option-setting-blsel-sel@86c2e9f0 {
				compatible = "zephyr,memory-region";
				reg = <0x86c2e9f0 0x4>;
				zephyr,memory-region = "OPTION_SETTING_BLSEL_SEL";
				status = "disabled";
			};

			option_setting_bpsdm_sec: option-setting-bpsdm-sec@86c9f080 {
				compatible = "zephyr,memory-region";
				reg = <0x86c9f080 0x20>;
				zephyr,memory-region = "OPTION_SETTING_BPSDM_SEC";
				status = "disabled";
			};

			option_setting_bps_sec: option-setting-bps-sec@86c9f200 {
				compatible = "zephyr,memory-region";
				reg = <0x86c9f200 0x40>;
				zephyr,memory-region = "OPTION_SETTING_BPS_SEC";
				status = "disabled";
			};

			option_setting_bps_sec_dual: option-setting-bps-sec-dual@86c9f300 {
				compatible = "zephyr,memory-region";
				reg = <0x86c9f300 0x20>;
				zephyr,memory-region = "OPTION_SETTING_BPS_SEC_DUAL";
				status = "disabled";
			};
		};

		option_setting_opt_sec: option-setting-opt-sec@86e00000 {
			compatible = "renesas,ofs-memory";
			reg = <0x86e00000 0x00030ef0>;
			#address-cells = <1>;
			#size-cells = <1>;
			status = "disabled";

			// option_setting_data_flash_hoemrtpk: option-setting-data-flash-hoemrtpk@86e00000 {
			// 	compatible = "zephyr,memory-region";
			// 	reg = <0x86e00000 0xc0>;
			//      zephyr,memory-region = "OPTION_SETTING_DATA_FLASH_HOEMRTPK";
			// 	status = "okay";
			// };

			option_setting_data_flash_fsblctrl0: option-setting-data-flash-fsblctrl@86e00400 {
				compatible = "zephyr,memory-region";
				reg = <0x86e00400 0x4>;
				zephyr,memory-region = "OPTION_SETTING_DATA_FLASH_FSBLCTRL0";
				status = "disabled";
			};

			option_setting_data_flash_fsblctrl1: option-setting-data-flash-fsblctrl@86e00404 {
				compatible = "zephyr,memory-region";
				reg = <0x86e00404 0x4>;
				zephyr,memory-region = "OPTION_SETTING_DATA_FLASH_FSBLCTRL1";
				status = "disabled";
			};

			option_setting_data_flash_fsblctrl2: option-setting-data-flash-fsblctrl2@86e00408 {
				compatible = "zephyr,memory-region";
				reg = <0x86e00408 0x4>;
				zephyr,memory-region = "OPTION_SETTING_DATA_FLASH_FSBLCTRL2";
				status = "disabled";
			};

			option_setting_data_flash_samr: option-setting-data-flash-samr@86e00414 {
				compatible = "zephyr,memory-region";
				reg = <0x86e00414 0x4>;
				zephyr,memory-region = "OPTION_SETTING_DATA_FLASH_SAMR";
				status = "disabled";
			};

			option_setting_data_flash_sacc0: option-setting-data-flash-sacc0@86e00420 {
				compatible = "zephyr,memory-region";
				reg = <0x86e00420 0x4>;
				zephyr,memory-region = "OPTION_SETTING_DATA_FLASH_SACC0";
				status = "disabled";
			};

			option_setting_data_flash_sacc10: option-setting-data-flash-sacc10@86e00430 {
				compatible = "zephyr,memory-region";
				reg = <0x86e00430 0x4>;
				zephyr,memory-region = "OPTION_SETTING_DATA_FLASH_SACC10";
				status = "disabled";
			};

			option_setting_data_flash_sacc1: option-setting-data-flash-sacc1@86e00440 {
				compatible = "zephyr,memory-region";
				reg = <0x86e00440 0x4>;
				zephyr,memory-region = "OPTION_SETTING_DATA_FLASH_SACC1";
				status = "disabled";
			};

			option_setting_data_flash_sacc11: option-setting-data-flash-sacc11@86e00450 {
				compatible = "zephyr,memory-region";
				reg = <0x86e00450 0x4>;
				zephyr,memory-region = "OPTION_SETTING_DATA_FLASH_SACC11";
				status = "disabled";
			};

			option_setting_data_flash_sacc2: option-setting-data-flash-sacc2@86e00460 {
				compatible = "zephyr,memory-region";
				reg = <0x86e00460 0x4>;
				zephyr,memory-region = "OPTION_SETTING_DATA_FLASH_SACC2";
				status = "disabled";
			};


			option_setting_data_flash_sacc12: option-setting-data-flash-sacc2@86e00470 {
				compatible = "zephyr,memory-region";
				reg = <0x86e00470 0x4>;
				zephyr,memory-region = "OPTION_SETTING_DATA_FLASH_SACC12";
				status = "disabled";
			};

			option_setting_data_flash_sacc3: option-setting-data-flash-sacc3@86e00480 {
				compatible = "zephyr,memory-region";
				reg = <0x86e00480 0x4>;
				zephyr,memory-region = "OPTION_SETTING_DATA_FLASH_SACC3";
				status = "disabled";
			};

			option_setting_data_flash_sacc13: option-setting-data-flash-sacc13@86e00490 {
				compatible = "zephyr,memory-region";
				reg = <0x86e00490 0x4>;
				zephyr,memory-region = "OPTION_SETTING_DATA_FLASH_SACC13";
				status = "disabled";
			};

			option_setting_gpotp: option-setting-gpotp@86e004a0 {
				compatible = "zephyr,memory-region";
				reg = <0x86e004a0 0x60>;
				zephyr,memory-region = "OPTION_SETTING_GPOTP";
				status = "disabled";
			};

			option_setting_ofs0: option-setting-ofs0@86e10640 {
				compatible = "zephyr,memory-region";
				reg = <0x86e10640 0x4>;
				zephyr,memory-region = "OPTION_SETTING_OFS0";
				status = "disabled";
			};

			option_setting_ofs2: option-setting-ofs2@86e10644 {
				compatible = "zephyr,memory-region";
				reg = <0x86e10644 0x4>;
				zephyr,memory-region = "OPTION_SETTING_OFS2";
				status = "disabled";
			};

			option_setting_mde: option-setting-mde@86e1064c {
				compatible = "zephyr,memory-region";
				reg = <0x86e1064c 0x4>;
				zephyr,memory-region = "OPTION_SETTING_MDE";
				status = "disabled";
			};

			option_setting_ofs1_sec: option-setting-ofs1-sec@86e107a0 {
				compatible = "zephyr,memory-region";
				reg = <0x86e107a0 0x4>;
				zephyr,memory-region = "OPTION_SETTING_OFS1_SEC";
				status = "disabled";
			};

			option_setting_ofs3_sec: option-setting-ofs3-sec@86e107a4 {
				compatible = "zephyr,memory-region";
				reg = <0x86e107a4 0x4>;
				zephyr,memory-region = "OPTION_SETTING_OFS3_SEC";
				status = "disabled";
			};

			option_setting_ofs1_sel: option-setting-ofs1-sel@86e107d0 {
				compatible = "zephyr,memory-region";
				reg = <0x86e107d0 0x4>;
				zephyr,memory-region = "OPTION_SETTING_OFS1_SEL";
				status = "disabled";
			};

			option_setting_ofs3_sel: option-setting-ofs3-sel@86e107d4 {
				compatible = "zephyr,memory-region";
				reg = <0x86e107d4 0x4>;
				zephyr,memory-region = "OPTION_SETTING_OFS3_SEL";
				status = "disabled";
			};

			option_setting_pbps_sec: option-setting-pbps-sec@86e10a00 {
				compatible = "zephyr,memory-region";
				reg = <0x86e10a00 0x10>;
				zephyr,memory-region = "OPTION_SETTING_PBPS_SEC";
				status = "disabled";
			};

			option_setting_pbps_sec_dual: option-setting-pbps-sec-dual@86e10a40 {
				compatible = "zephyr,memory-region";
				reg = <0x86e10a40 0x8>;
				zephyr,memory-region = "OPTION_SETTING_PBPS_SEC_DUAL";
				status = "disabled";
			};

			option_setting_pbpsdm_sec: option-setting-pbpsdm-sec@86e10a80 {
				compatible = "zephyr,memory-region";
				reg = <0x86e10a80 0x4>;
				zephyr,memory-region = "OPTION_SETTING_PBPSDM_SEC";
				status = "disabled";
			};

			option_setting_revoke: option-setting-revoke@86e30e10 {
				compatible = "zephyr,memory-region";
				reg = <0x86e30e10 0x4>;
				zephyr,memory-region = "OPTION_SETTING_REVOKE";
				status = "disabled";
			};

			option_setting_zhuk: option-setting-zhuk@86e30e20 {
				compatible = "zephyr,memory-region";
				reg = <0x86e30e20 0x4>;
				zephyr,memory-region = "OPTION_SETTING_ZHUK";
				status = "disabled";
			};

			option_setting_arccs: option-setting-arccs@86e30e30 {
				compatible = "zephyr,memory-region";
				reg = <0x86e30e30 0x4>;
				zephyr,memory-region = "OPTION_SETTING_ARCCS";
				status = "disabled";
			};

			option_setting_ubcsr: option-setting-ufbcsr@86e30e50 {
				compatible = "zephyr,memory-region";
				reg = <0x86e30e50 0x4>;
				zephyr,memory-region = "OPTION_SETTING_UBCSR";
				status = "disabled";
			};

			option_setting_ofsps: option-setting-ofsps@86e30e60 {
				compatible = "zephyr,memory-region";
				reg = <0x86e30e60 0x10>;
				zephyr,memory-region = "OPTION_SETTING_OFSPS";
				status = "disabled";
			};

			/* Since the RFP tool currently does not support the following OFS regions,
			* they have been temporarily commented out to enable flashing via RFP.
			*/

			// option_setting_ofsps2: option-setting-ofsps2@86e30ee0 {
			// 	compatible = "zephyr,memory-region";
			// 	reg = <0x86e30ee0 0x4>;
			// 	status = "okay";
			// };
		};

		// option_setting_anti_rollback_sec: option-setting-anti-rollback-sec@86f41d00 {
		// 	compatible = "zephyr,memory-region";
		// 	reg = <0x86f41d00 0x00000210>;
		// 	zephyr,memory-region = "OFS_ANTI_ROLLBACK_SEC";
		// 	#address-cells = <1>;
		// 	#size-cells = <0>;
		// 	status = "okay";

		// 	option_setting_arcs: option-setting-arcs@86f41d00 {
		// 		compatible = "zephyr,memory-region";
		// 		reg = <0x86f41d00 0x80>;
		// 		status = "okay";
		// 	};

		// 	option_setting_arcnsn: option-setting-arcnsn@86f41e00 {
		// 		compatible = "zephyr,memory-region";
		// 		reg = <0x86f41e00 0x80>;
		// 		status = "okay";
		// 	};

		// 	option_setting_arcns: option-setting-arcns0@86f41e00 {
		// 		compatible = "zephyr,memory-region";
		// 		reg = <0x86f41e00 0x80>;
		// 		status = "okay";
		// 	};

		// 	option_setting_arcoembl: option-setting-arcoembl@86f41f00 {
		// 		compatible = "zephyr,memory-region";
		// 		reg = <0x86f41f00 0x8>;
		// 		status = "okay";
		// 	};
		// };

		group_irq_il0: grp_intc@87006550 {
			compatible = "renesas,rx-grp-intc-fsp";
			interrupt-controller;
			label = "il0";
			reg =	<0x87006550 0x04>,
			<0x87006570 0x04>;
			reg-names = "GRP", "GEN";
			interrupts = <17 4>;
			status = "disabled";
			#interrupt-cells = <2>;
		};

		group_irq_bl0: grp_intc@87006640 {
			compatible = "renesas,rx-grp-intc-fsp";
			interrupt-controller;
			label = "bl0";
			reg =	<0x87006640 0x04>,
			<0x870066c0 0x04>;
			reg-names = "GRP", "GEN";
			interrupts = <102 4>;
			status = "disabled";
			#interrupt-cells = <2>;
		};

		group_irq_bl1: grp_intc@87006644 {
			compatible = "renesas,rx-grp-intc-fsp";
			interrupt-controller;
			label = "bl1";
			reg =	<0x87006644 0x04>,
			<0x870066c4 0x04>;
			reg-names = "GRP", "GEN";
			interrupts = <103 4>;
			status = "disabled";
			#interrupt-cells = <2>;
		};

		group_irq_al0: grp_intc@87006740 {
			compatible = "renesas,rx-grp-intc-fsp";
			interrupt-controller;
			label = "al0";
			reg =	<0x87006740 0x04>,
			<0x870067c0 0x04>;
			reg-names = "GRP", "GEN";
			interrupts = <104 4>;
			status = "disabled";
			#interrupt-cells = <2>;
		};

		group_irq_al1: grp_intc@87006744 {
			compatible = "renesas,rx-grp-intc-fsp";
			interrupt-controller;
			label = "al1";
			reg =	<0x87006744 0x04>,
			<0x870067c4 0x04>;
			reg-names = "GRP", "GEN";
			interrupts = <105 4>;
			status = "disabled";
			#interrupt-cells = <2>;
		};

		group_irq_al2: grp_intc@87006748 {
			compatible = "renesas,rx-grp-intc-fsp";
			interrupt-controller;
			label = "al2";
			reg =	<0x87006748 0x04>,
			<0x870067c8 0x04>;
			reg-names = "GRP", "GEN";
			interrupts = <106 4>;
			status = "disabled";
			#interrupt-cells = <2>;
		};

		group_irq_al3: grp_intc@8700674c {
			compatible = "renesas,rx-grp-intc-fsp";
			interrupt-controller;
			label = "al3";
			reg =	<0x8700674c 0x04>,
			<0x870067cc 0x04>;
			reg-names = "GRP", "GEN";
			interrupts = <107 4>;
			status = "disabled";
			#interrupt-cells = <2>;
		};

		group_irq_al4: grp_intc@87006750 {
			compatible = "renesas,rx-grp-intc-fsp";
			interrupt-controller;
			label = "al4";
			reg =	<0x87006750 0x04>,
			<0x870067d0 0x04>;
			reg-names = "GRP", "GEN";
			interrupts = <108 4>;
			status = "disabled";
			#interrupt-cells = <2>;
		};

		group_irq_al5: grp_intc@87006754 {
			compatible = "renesas,rx-grp-intc-fsp";
			interrupt-controller;
			label = "al5";
			reg =	<0x87006754 0x04>,
			<0x870067d4 0x04>;
			reg-names = "GRP", "GEN";
			interrupts = <109 4>;
			status = "disabled";
			#interrupt-cells = <2>;
		};

		group_irq_al6: grp_intc@87006758 {
			compatible = "renesas,rx-grp-intc-fsp";
			interrupt-controller;
			label = "al6";
			reg =	<0x87006758 0x04>,
			<0x870067d8 0x04>;
			reg-names = "GRP", "GEN";
			interrupts = <110 4>;
			status = "disabled";
			#interrupt-cells = <2>;
		};

		canfd_global: canfd_global@87480000 {
			compatible = "renesas,rx-canfd-global";
			interrupts-extended = <&group_irq_al2 0 1>,
					      <&group_irq_al2 1 1>;
			interrupt-names = "rfri", "glei";
			clocks = <&pclka 0 0>, <&pclke 0 0>;
			clock-names = "opclk", "ramclk";
			dll-min-freq = <0>;
			dll-max-freq = <80000000>;
			reg = <0x87480000 0x20>;
			status = "disabled";

			canfd0: canfd0 {
				compatible = "renesas,rx-canfd";
				channel = <0>;
				interrupts-extended = <&group_irq_al2 2 1>,
						      <&group_irq_al2 3 1>,
						      <&group_irq_al2 4 1>;
				interrupt-names = "chti", "chei", "chri";
				clocks = <&canfdclk MSTPC 27>;
				clock-names = "dllclk";
				status = "disabled";
			};

			canfd1: canfd1 {
				compatible = "renesas,rx-canfd";
				channel = <1>;
				interrupts-extended = <&group_irq_al2 5 1>,
						      <&group_irq_al2 6 1>,
						      <&group_irq_al2 7 1>;
				interrupt-names = "chti", "chei", "chri";
				clocks = <&canfdclk MSTPC 27>;
				clock-names = "dllclk";
				status = "disabled";
			};
		};

	};
};
